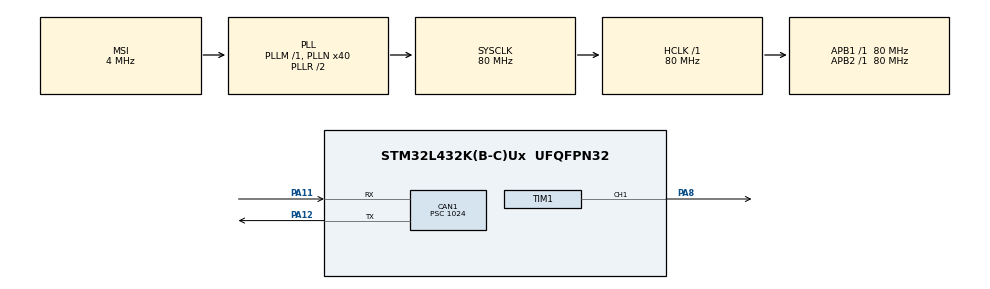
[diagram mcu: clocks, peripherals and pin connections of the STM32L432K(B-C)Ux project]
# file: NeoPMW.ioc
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CAN1.BS1=CAN_BS1_8TQ
CAN1.BS2=CAN_BS2_2TQ
CAN1.CalculateBaudRate=7102
CAN1.CalculateTimeBit=140800
CAN1.CalculateTimeQuantum=12800.0
CAN1.Prescaler=1024
CAN1.SJW=CAN_SJW_1TQ
Mcu.Family=STM32L4
Mcu.Name=STM32L432K(B-C)Ux
Mcu.Package=UFQFPN32
NVIC.PriorityGroup=NVIC_PRIORITYGROUP_4
PA11.Mode=CAN_Activate
PA11.Signal=CAN1_RX
PA12.Mode=CAN_Activate
PA12.Signal=CAN1_TX
PA8.Signal=S_TIM1_CH1
PA9.Signal=S_TIM1_CH2
ProjectManager.HeapSize=0x200
ProjectManager.StackSize=0x400
ProjectManager.TargetToolchain=STM32CubeIDE
RCC.AHBFreq_Value=80000000
RCC.APB1Freq_Value=80000000
RCC.APB1TimFreq_Value=80000000
RCC.APB2Freq_Value=80000000
RCC.APB2TimFreq_Value=80000000
RCC.CortexFreq_Value=80000000
RCC.HCLKFreq_Value=80000000
RCC.HSE_VALUE=8000000
RCC.HSI48_VALUE=48000000
RCC.HSI_VALUE=16000000
RCC.LSE_VALUE=32768
RCC.MSI_VALUE=4000000
RCC.PLLN=40
RCC.SYSCLKFreq_VALUE=80000000
RCC.SYSCLKSource=RCC_SYSCLKSOURCE_PLLCLK
RCC.VCOOutputFreq_Value=160000000
SH.S_TIM1_CH1.0=TIM1_CH1,PWM Generation1 CH1
SH.S_TIM1_CH2.0=TIM1_CH2
TIM1.Channel-PWM\ Generation1\ CH1=TIM_CHANNEL_1
TIM1.Period=95
VP_TIM1_VS_ClockSourceINT.Mode=Internal
board=custom

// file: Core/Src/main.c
/* USER CODE BEGIN Header */
/**
  ******************************************************************************
  * @file           : main.c
  * @brief          : Main program body
  ******************************************************************************
  * @attention
  *
  * Copyright (c) 2023 STMicroelectronics.
  * All rights reserved.
  *
  * This software is licensed under terms that can be found in the LICENSE file
  * in the root directory of this software component.
  * If no LICENSE file comes with this software, it is provided AS-IS.
  *
  ******************************************************************************
  */
/* USER CODE END Header */
#include "main.h"

/* USER CODE BEGIN PTD */
typedef union
{
  struct
  {
    uint8_t b;
    uint8_t r;
    uint8_t g;
  } color;
  uint32_t data;
} PixelRGB_t;
/* USER CODE END PTD */

/* USER CODE BEGIN PD */
#define NEOPIXEL_ZERO 31
#define NEOPIXEL_ONE 61
#define	NUM_PIXELS 12
#define DMA_BUFF_SIZE (NUM_PIXELS * 24) + 1

#define COLOR_RED (int[]){255, 0, 0}
#define COLOR_GREEN (int[]){0, 255, 0}
#define COLOR_BLUE (int[]){0, 0, 255}
#define COLOR_CYAN (int[]){0, 255, 255}
#define COLOR_MAGENTA (int[]){255, 0, 255}
#define COLOR_YELLOW (int[]){255, 255, 0}
#define COLOR_WHITE (int[]){255, 255, 255}

#define INTENSITY_VERY_LOW 7
#define INTENSITY_LOW 6
#define INTENSITY_MIDDLE 4
#define INTENSITY_HIGH 2
#define INTENSITY_VERY_HIGH 0
/* USER CODE END PD */

CAN_HandleTypeDef hcan1;

TIM_HandleTypeDef htim1;

/* USER CODE BEGIN PV */

char buffer[1024]; // Initialisation d'une variable de stockage
uint16_t Tx_len;
PMW3901_Status_t status;
int16_t var_x,var_y; // Initialisation de la variation

float posX = 0; // Initialisation des variables de position
float posY = 0;

float dx = 0; // Initialisation des variables de déplacement
float dy = 0;

PMW3901_Descriptor_t PMW3901_Descriptor = {
		.hspi = &hspi1,
		.CS_Port = SPI1_CS_GPIO_Port,
		.CS_Pin = SPI1_CS_Pin
}; // Initialise le port SPI

/* USER CODE END PV */

void SystemClock_Config(void);
static void MX_GPIO_Init(void);
static void MX_TIM1_Init(void);
static void MX_CAN1_Init(void);
/* USER CODE BEGIN PFP */
void SystemClock_Config(void);
static void MX_GPIO_Init(void);
static void MX_USART2_UART_Init(void);
static void MX_SPI1_Init(void);
static void MX_CAN1_Init(void);
static void MX_I2C1_Init(void);
static void MX_DMA_Init(void);
static void MX_TIM1_Init(void);
/* USER CODE END PFP */

/* USER CODE BEGIN 0 */
void HAL_TIM_PWM_PulseFinishedCallback(TIM_HandleTypeDef *htim)
{
  HAL_TIM_PWM_Stop_DMA(htim, TIM_CHANNEL_1);
}

void NEOPIXELS_SETUP(PixelRGB_t pixel[], uint32_t *dmaBuffer, uint32_t *pBuff, int numPixelsOn, int k, int modulo, int color[], int intensity)
{
	for (int i = (NUM_PIXELS - 1); i > 0; i--)
	{
		pixel[i].data = pixel[i-1].data;
	}

	if((k % modulo) != 0)
	{
		pixel[0].color.r = 0;
		pixel[0].color.g = 0;
		pixel[0].color.b = 0;
	}

	else
	{
		pixel[0].color.r = color[0];
		pixel[0].color.g = color[1];
		pixel[0].color.b = color[2];
	}

	pixel[0].color.g >>= intensity;
	pixel[0].color.r >>= intensity;
	pixel[0].color.b >>= intensity;

	pBuff = dmaBuffer;

	for (int i = 0; i < numPixelsOn; i++)
	{
		for (int j = 23; j >= 0; j--)
	    {
			if (((pixel[i].data >> j) & 0x01) && ((k % modulo) == 0))
	        {
				*pBuff = NEOPIXEL_ONE;
	        }
	        else
	        {
	        	*pBuff = NEOPIXEL_ZERO;
	        }
	        pBuff++;
	     }
	 }
	 dmaBuffer[DMA_BUFF_SIZE - 1] = 0;
}
/* USER CODE END 0 */

int main(void)
{
  /* USER CODE BEGIN 1 */
  PixelRGB_t pixel[NUM_PIXELS] = {0};
  uint32_t dmaBuffer[DMA_BUFF_SIZE] = {0};
  uint32_t *pBuff = NULL;
  int k, modulo, numPixelsOff = 0, numPixelsOn;
  /* USER CODE END 1 */

  /* MCU Configuration--------------------------------------------------------*/

  /* Reset of all peripherals, Initializes the Flash interface and the Systick. */
  HAL_Init();

  /* Configure the system clock */
  SystemClock_Config();

  /* Initialize all configured peripherals */
  MX_GPIO_Init();
  MX_TIM1_Init();
  MX_CAN1_Init();

  /* Infinite loop */
  /* USER CODE BEGIN WHILE */
  numPixelsOn = NUM_PIXELS - numPixelsOff;

  modulo = 3;
  for(int m = 0; m < numPixelsOn; m++)
  {
  	  NEOPIXELS_SETUP(pixel, dmaBuffer, pBuff, numPixelsOn, m, modulo, COLOR_GREEN, INTENSITY_HIGH);
  	  HAL_Delay(500);
  	  HAL_TIM_PWM_Start_DMA(&htim1, TIM_CHANNEL_1, dmaBuffer, DMA_BUFF_SIZE);
  }
  HAL_Delay(1000);

  k = 0;
  modulo = 1;
  while (1)
  {
	  for(int m = 0; m < numPixelsOn; m++){
	  		NEOPIXELS_SETUP(pixel, dmaBuffer, pBuff, numPixelsOn, m, modulo, COLOR_BLUE, INTENSITY_MIDDLE);
	  		HAL_TIM_PWM_Start_DMA(&htim1, TIM_CHANNEL_1, dmaBuffer, DMA_BUFF_SIZE);
	  		HAL_Delay(0);
	  	}
	  	HAL_Delay(100);

	  	for(int m = 0; m < numPixelsOn; m++){
	  		NEOPIXELS_SETUP(pixel, dmaBuffer, pBuff, numPixelsOn, m, modulo, COLOR_GREEN, INTENSITY_MIDDLE);
	  		HAL_TIM_PWM_Start_DMA(&htim1, TIM_CHANNEL_1, dmaBuffer, DMA_BUFF_SIZE);
	  		HAL_Delay(0);
	  	}
	  	HAL_Delay(100);

	  	for(int m = 0; m < numPixelsOn; m++){
	  		NEOPIXELS_SETUP(pixel, dmaBuffer, pBuff, numPixelsOn, m, modulo, COLOR_RED, INTENSITY_MIDDLE);
	  		HAL_TIM_PWM_Start_DMA(&htim1, TIM_CHANNEL_1, dmaBuffer, DMA_BUFF_SIZE);
	  		HAL_Delay(0);
	  	}
	  	HAL_Delay(100);
	  	k++;
    /* USER CODE END WHILE */

  }
}

void SystemClock_Config(void)
{
  RCC_OscInitTypeDef RCC_OscInitStruct = {0};
  RCC_ClkInitTypeDef RCC_ClkInitStruct = {0};

  /** Configure the main internal regulator output voltage
  */
  if (HAL_PWREx_ControlVoltageScaling(PWR_REGULATOR_VOLTAGE_SCALE1) != HAL_OK)
  {
    Error_Handler();
  }

  /** Initializes the RCC Oscillators according to the specified parameters
  * in the RCC_OscInitTypeDef structure.
  */
  RCC_OscInitStruct.OscillatorType = RCC_OSCILLATORTYPE_MSI;
  RCC_OscInitStruct.MSIState = RCC_MSI_ON;
  RCC_OscInitStruct.MSICalibrationValue = 0;
  RCC_OscInitStruct.MSIClockRange = RCC_MSIRANGE_6;
  RCC_OscInitStruct.PLL.PLLState = RCC_PLL_ON;
  RCC_OscInitStruct.PLL.PLLSource = RCC_PLLSOURCE_MSI;
  RCC_OscInitStruct.PLL.PLLM = 1;
  RCC_OscInitStruct.PLL.PLLN = 40;
  RCC_OscInitStruct.PLL.PLLP = RCC_PLLP_DIV7;
  RCC_OscInitStruct.PLL.PLLQ = RCC_PLLQ_DIV2;
  RCC_OscInitStruct.PLL.PLLR = RCC_PLLR_DIV2;
  if (HAL_RCC_OscConfig(&RCC_OscInitStruct) != HAL_OK)
  {
    Error_Handler();
  }

  /** Initializes the CPU, AHB and APB buses clocks
  */
  RCC_ClkInitStruct.ClockType = RCC_CLOCKTYPE_HCLK|RCC_CLOCKTYPE_SYSCLK
                              |RCC_CLOCKTYPE_PCLK1|RCC_CLOCKTYPE_PCLK2;
  RCC_ClkInitStruct.SYSCLKSource = RCC_SYSCLKSOURCE_PLLCLK;
  RCC_ClkInitStruct.AHBCLKDivider = RCC_SYSCLK_DIV1;
  RCC_ClkInitStruct.APB1CLKDivider = RCC_HCLK_DIV1;
  RCC_ClkInitStruct.APB2CLKDivider = RCC_HCLK_DIV1;

  if (HAL_RCC_ClockConfig(&RCC_ClkInitStruct, FLASH_LATENCY_4) != HAL_OK)
  {
    Error_Handler();
  }
}

static void MX_CAN1_Init(void)
{

  hcan1.Instance = CAN1;
  hcan1.Init.Prescaler = 1024;
  hcan1.Init.Mode = CAN_MODE_NORMAL;
  hcan1.Init.SyncJumpWidth = CAN_SJW_1TQ;
  hcan1.Init.TimeSeg1 = CAN_BS1_8TQ;
  hcan1.Init.TimeSeg2 = CAN_BS2_2TQ;
  hcan1.Init.TimeTriggeredMode = DISABLE;
  hcan1.Init.AutoBusOff = DISABLE;
  hcan1.Init.AutoWakeUp = DISABLE;
  hcan1.Init.AutoRetransmission = DISABLE;
  hcan1.Init.ReceiveFifoLocked = DISABLE;
  hcan1.Init.TransmitFifoPriority = DISABLE;
  if (HAL_CAN_Init(&hcan1) != HAL_OK)
  {
    Error_Handler();
  }

}

static void MX_TIM1_Init(void)
{

  TIM_ClockConfigTypeDef sClockSourceConfig = {0};
  TIM_MasterConfigTypeDef sMasterConfig = {0};
  TIM_OC_InitTypeDef sConfigOC = {0};
  TIM_BreakDeadTimeConfigTypeDef sBreakDeadTimeConfig = {0};

  htim1.Instance = TIM1;
  htim1.Init.Prescaler = 0;
  htim1.Init.CounterMode = TIM_COUNTERMODE_UP;
  htim1.Init.Period = 95;
  htim1.Init.ClockDivision = TIM_CLOCKDIVISION_DIV1;
  htim1.Init.RepetitionCounter = 0;
  htim1.Init.AutoReloadPreload = TIM_AUTORELOAD_PRELOAD_DISABLE;
  if (HAL_TIM_Base_Init(&htim1) != HAL_OK)
  {
    Error_Handler();
  }
  sClockSourceConfig.ClockSource = TIM_CLOCKSOURCE_INTERNAL;
  if (HAL_TIM_ConfigClockSource(&htim1, &sClockSourceConfig) != HAL_OK)
  {
    Error_Handler();
  }
  if (HAL_TIM_PWM_Init(&htim1) != HAL_OK)
  {
    Error_Handler();
  }
  sMasterConfig.MasterOutputTrigger = TIM_TRGO_RESET;
  sMasterConfig.MasterOutputTrigger2 = TIM_TRGO2_RESET;
  sMasterConfig.MasterSlaveMode = TIM_MASTERSLAVEMODE_DISABLE;
  if (HAL_TIMEx_MasterConfigSynchronization(&htim1, &sMasterConfig) != HAL_OK)
  {
    Error_Handler();
  }
  sConfigOC.OCMode = TIM_OCMODE_PWM1;
  sConfigOC.Pulse = 0;
  sConfigOC.OCPolarity = TIM_OCPOLARITY_HIGH;
  sConfigOC.OCNPolarity = TIM_OCNPOLARITY_HIGH;
  sConfigOC.OCFastMode = TIM_OCFAST_DISABLE;
  sConfigOC.OCIdleState = TIM_OCIDLESTATE_RESET;
  sConfigOC.OCNIdleState = TIM_OCNIDLESTATE_RESET;
  if (HAL_TIM_PWM_ConfigChannel(&htim1, &sConfigOC, TIM_CHANNEL_1) != HAL_OK)
  {
    Error_Handler();
  }
  sBreakDeadTimeConfig.OffStateRunMode = TIM_OSSR_DISABLE;
  sBreakDeadTimeConfig.OffStateIDLEMode = TIM_OSSI_DISABLE;
  sBreakDeadTimeConfig.LockLevel = TIM_LOCKLEVEL_OFF;
  sBreakDeadTimeConfig.DeadTime = 0;
  sBreakDeadTimeConfig.BreakState = TIM_BREAK_DISABLE;
  sBreakDeadTimeConfig.BreakPolarity = TIM_BREAKPOLARITY_HIGH;
  sBreakDeadTimeConfig.BreakFilter = 0;
  sBreakDeadTimeConfig.Break2State = TIM_BREAK2_DISABLE;
  sBreakDeadTimeConfig.Break2Polarity = TIM_BREAK2POLARITY_HIGH;
  sBreakDeadTimeConfig.Break2Filter = 0;
  sBreakDeadTimeConfig.AutomaticOutput = TIM_AUTOMATICOUTPUT_DISABLE;
  if (HAL_TIMEx_ConfigBreakDeadTime(&htim1, &sBreakDeadTimeConfig) != HAL_OK)
  {
    Error_Handler();
  }
  HAL_TIM_MspPostInit(&htim1);

}

static void MX_GPIO_Init(void)
{

  /* GPIO Ports Clock Enable */
  __HAL_RCC_GPIOA_CLK_ENABLE();

}

void Error_Handler(void)
{
  __disable_irq();
  while (1)
  {
  }
}
